# max32690 register map
Vendor: Maxim-Integrated; Series: ARMCM4; File version: 1.2
CPU: CM4 r2p1, little endian, MPU, FPU, 3 interrupt priority bits
Registers are 32-bit, read-write, reset 0x0 unless marked. A register's access mark holds for its fields unless they carry their own. Offsets are from the block's base; [hi:lo] are bit positions; {n}, {i} and the like mark numbered series.

## FLC — Flash Memory Control.
Base 0x40029000; register names take the prefix FLSH_
0x00 ADDR — Flash Write Address.
  [31:0] ADDR — Address for next operation.
0x04 CLKDIV reset 0x78 — Flash Clock Divide. The clock (PLL0) is divided by this value to generate a 1 MHz clock for Flash controller.
  [7:0] CLKDIV — Flash Clock Divide. The clock is divided by this value to generate a 1MHz clock for flash controller.
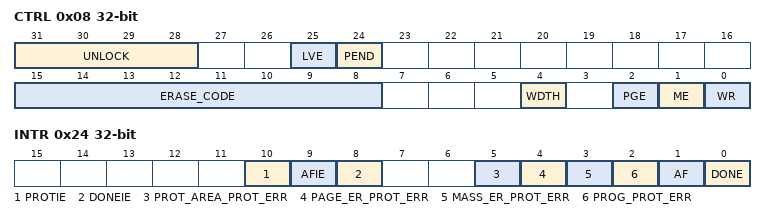
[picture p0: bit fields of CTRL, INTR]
0x08 CTRL — Flash Control Register.
  [31:28] UNLOCK — Flash Unlock. The correct unlock code must be written to these four bits before any Flash write or erase operation is allowed.
    2=unlocked (Flash Unlocked.); 3=locked (Flash Locked.)
  [25] LVE — Low Voltage enable.
  [24] PEND ro — Flash Pending. When Flash operation is in progress (busy), Flash reads and writes will fail. When PEND is set, write to all Flash registers, with exception of the Flash interrupt register, are ignored.
    0=idle; 1=busy
  [15:8] ERASE_CODE — Erase Code. The ERASE_CODE must be set up property before erase operation can be initiated. These bits are automatically cleared after the operation is complete.
    0=nop (No operation.); 85=erasePage (Enable Page Erase.); 170=eraseAll (Enable Mass Erase. The debug port must be enabled.)
  [4] WDTH
  [2] PGE — Page Erase. This bit is automatically cleared after the operation.
    0=complete (No operation/complete.); 1=Start operation
  [1] ME — Mass Erase. This bit is automatically cleared after the operation.
    0=complete (No operation/complete.); 1=Start operation
  [0] WR — Write. This bit is automatically cleared after the operation.
    0=complete (No operation/complete.); 1=Start operation
0x24 INTR — Flash Interrupt Register.
  [10] PROTIE
    0=dis (Disable.); 1=en (Enable.)
  [9] AFIE
    0=dis (Disable.); 1=en (Enable.)
  [8] DONEIE — Flash Done Interrupt Enable.
    0=dis (Disable.); 1=en (Enable.)
  [5] PROT_AREA_PROT_ERR
    0=noerr (No Failure.); 1=error (Failure occurs.)
  [4] PAGE_ER_PROT_ERR
    0=noerr (No Failure.); 1=error (Failure occurs.)
  [3] MASS_ER_PROT_ERR
    0=noerr (No Failure.); 1=error (Failure occurs.)
  [2] PROG_PROT_ERR — Program Protection Error.
    0=noerr (No Failure.); 1=error (Failure occurs.)
  [1] AF — Flash Access Fail. This bit is set when an attempt is made to write the flash while the flash is busy or the flash is locked. This bit can only be set to 1 by hardware.
    0=noerr (No Failure.); 1=error (Failure occurs.)
  [0] DONE — Flash Done Interrupt. This bit is set to 1 upon Flash write or erase completion.
    0=inactive (No interrupt is pending.); 1=pending (An interrupt is pending.)
{0x30+4i} DATA[{i}] (i=0..3) — Flash Write Data.
  [31:0] DATA — Data next operation.
0x40 ACTRL wo — Access Control Register. Writing the ACNTL register with the following values in the order shown, allows read and write access to the system and user Information block: pflc-acntl = 0x3a7f5ca3; pflc-acntl = 0xa1e34f20; pflc-acntl = 0x9608b2c1. When unlocked, a write of any word will disable access to system and user information block. Readback of this register is always zero.
  [31:0] ACTRL — Access control.
{0x80+8i} WELR{i} (i=0..5) — Access control.
{0x84+8i} RLR{i} (i=0..5) — Access control.

## FLC1 — Flash Memory Control 1. Note: WELR2-5 and RLR2-5 are FLC0 only (UG Table 8-3).
Base 0x40029400; register names take the prefix FLSH_
Registers as FLC, without WELR{n} (n=2..5), RLR{n} (n=2..5).

## GCFR — Global Control Function Register.
Base 0x40005800
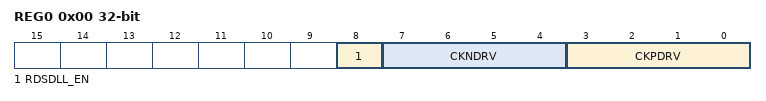
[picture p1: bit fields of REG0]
0x00 REG0 — Register 0.
  [8] RDSDLL_EN — Hyperbus RDS DLL Enable.
  [7:4] CKNDRV — Hyperbus CKN Drive Setting.
  [3:0] CKPDRV — Hyperbus CKP Drive Setting.
